# CEC1736_S0_2ZW register map
Vendor: Microchip Technology; Series: CEC; File version: 0
CPU: CM4 r1p0, little endian, MPU, FPU, 3 interrupt priority bits, 196 interrupts
Registers are 32-bit, read-write, reset 0x0 unless marked. A register's access mark holds for its fields unless they carry their own. Offsets are from the block's base; [hi:lo] are bit positions; {n}, {i} and the like mark numbered series; 'fields as' and 'values as' point back to an identical list.

## GPIO — GPIO Pin Control Registers
Base 0x40081000; register names take the prefix GPIO_
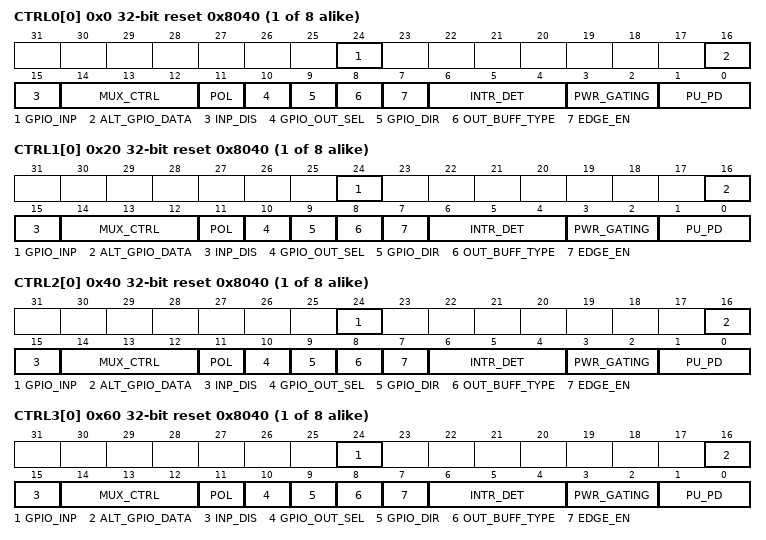
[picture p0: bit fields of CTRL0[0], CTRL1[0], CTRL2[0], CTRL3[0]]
{0x0+4i} CTRL0[{i}] (i=0..7) reset 0x8040 — GPIO Pin Control Register
  [24] GPIO_INP — GPIO input from pin, independent of the Mux selection for the pin or the Direction.
  [16] ALT_GPIO_DATA — GPIO Alternate Data Register.
  [15] INP_DIS — GPIO input disable
  [14:12] MUX_CTRL — 00 = GPIO Function, 01 = Function 1, 10 = Function 2, 11 = Function 3.
    0=GPIO (GPIO function selected); 1=FUNC1 (Signal function 1 selected); 2=FUNC2 (Signal function 2 selected); 3=FUNC3 (Signal function 3 selected)
  [11] POL — 1=Inverted; 0=Non-inverted
  [10] GPIO_OUT_SEL — GPIO outputs registe select.0=GPIO ALTERNATE_GPIO_DATA 1=GPIO Output Register.
  [9] GPIO_DIR — Buffer direction when GPIO selected by pin mux 0 = Input, 1 = Output
  [8] OUT_BUFF_TYPE — 0 = Push-Pull, 1 = Open Drain
  [7] EDGE_EN — Determines the interrupt capability of the GPIO input.
  [6:4] INTR_DET — Determines the interrupt capability of the GPIO input.
  [3:2] PWR_GATING — The GPIO pin will be tristated when the selected power well is off.
  [1:0] PU_PD — These bits are used to enable an internal pull-up or pull-down resistor.
    0=NONE (None. Pin tristates when no active driver is present on the pin.); 1=UP (Pull Up Enabled); 2=DOWN (Pull Down Enabled); 3=REPEATER (Repeater mode. Pin is kept at previous voltage level when no active driver is present on the pin.)
{0x20+4i} CTRL1[{i}] (i=0..7) reset 0x8040 — GPIO Pin Control Register
  fields as CTRL0[0]
{0x40+4i} CTRL2[{i}] (i=0..7) reset 0x8040 — GPIO Pin Control Register
  fields as CTRL0[0]
{0x60+4i} CTRL3[{i}] (i=0..7) reset 0x8040 — GPIO Pin Control Register
  fields as CTRL0[0]
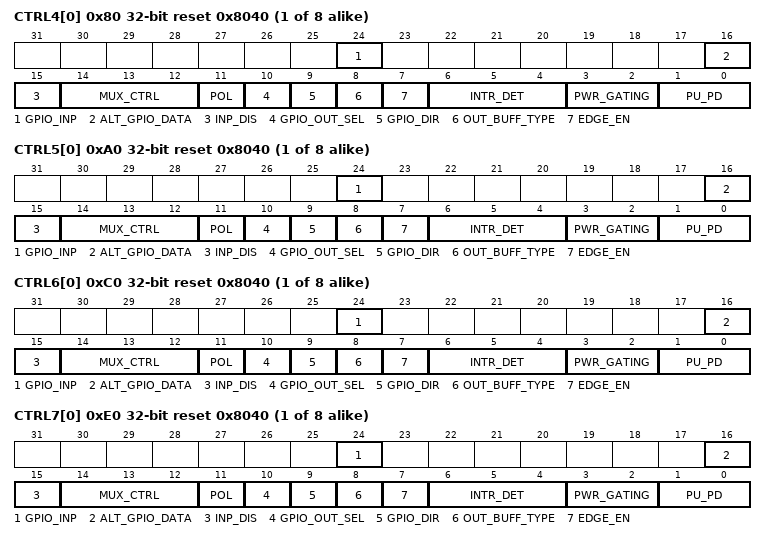
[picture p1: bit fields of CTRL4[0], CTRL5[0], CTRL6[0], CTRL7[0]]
{0x80+4i} CTRL4[{i}] (i=0..7) reset 0x8040 — GPIO Pin Control Register
  fields as CTRL0[0]
{0xA0+4i} CTRL5[{i}] (i=0..7) reset 0x8040 — GPIO Pin Control Register
  fields as CTRL0[0]
{0xC0+4i} CTRL6[{i}] (i=0..7) reset 0x8040 — GPIO Pin Control Register
  fields as CTRL0[0]
{0xE0+4i} CTRL7[{i}] (i=0..7) reset 0x8040 — GPIO Pin Control Register
  fields as CTRL0[0]
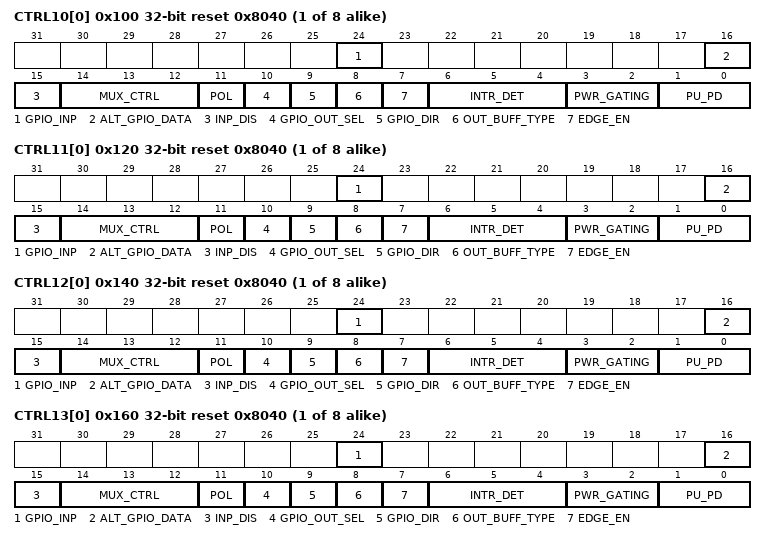
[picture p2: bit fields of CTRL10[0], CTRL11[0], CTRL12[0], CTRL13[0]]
{0x100+4i} CTRL10[{i}] (i=0..7) reset 0x8040 — GPIO Pin Control Register
  fields as CTRL0[0]
{0x120+4i} CTRL11[{i}] (i=0..7) reset 0x8040 — GPIO Pin Control Register
  fields as CTRL0[0]
{0x140+4i} CTRL12[{i}] (i=0..7) reset 0x8040 — GPIO Pin Control Register
  fields as CTRL0[0]
{0x160+4i} CTRL13[{i}] (i=0..7) reset 0x8040 — GPIO Pin Control Register
  fields as CTRL0[0]
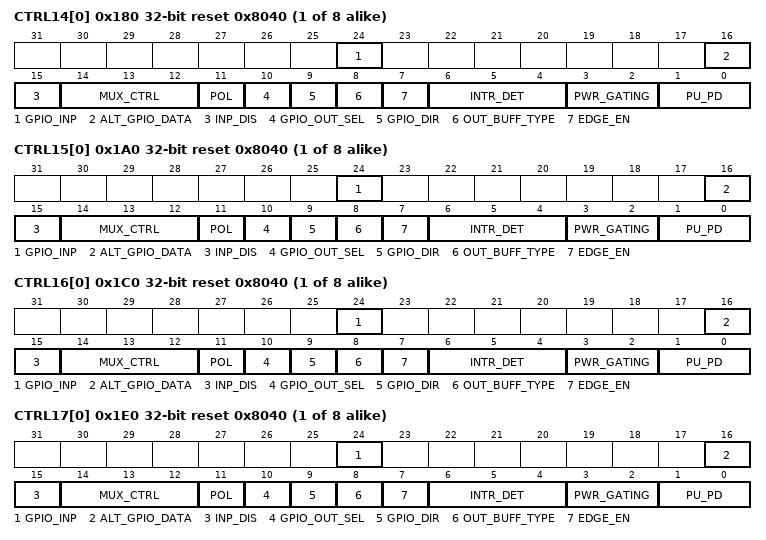
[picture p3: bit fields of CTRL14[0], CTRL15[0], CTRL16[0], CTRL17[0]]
{0x180+4i} CTRL14[{i}] (i=0..7) reset 0x8040 — GPIO Pin Control Register
  fields as CTRL0[0]
{0x1A0+4i} CTRL15[{i}] (i=0..7) reset 0x8040 — GPIO Pin Control Register
  fields as CTRL0[0]
{0x1C0+4i} CTRL16[{i}] (i=0..7) reset 0x8040 — GPIO Pin Control Register
  fields as CTRL0[0]
{0x1E0+4i} CTRL17[{i}] (i=0..7) reset 0x8040 — GPIO Pin Control Register
  fields as CTRL0[0]
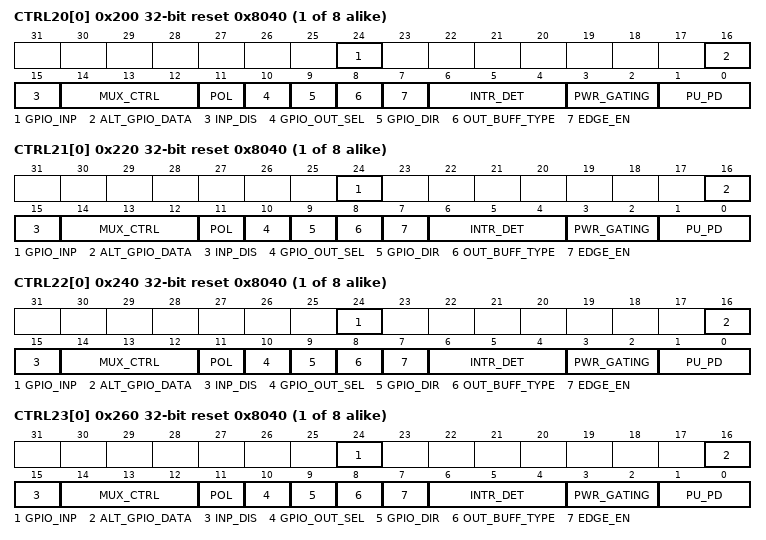
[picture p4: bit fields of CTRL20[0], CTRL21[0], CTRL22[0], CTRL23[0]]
{0x200+4i} CTRL20[{i}] (i=0..7) reset 0x8040 — GPIO Pin Control Register
  fields as CTRL0[0]
{0x220+4i} CTRL21[{i}] (i=0..7) reset 0x8040 — GPIO Pin Control Register
  fields as CTRL0[0]
{0x240+4i} CTRL22[{i}] (i=0..7) reset 0x8040 — GPIO Pin Control Register
  fields as CTRL0[0]
{0x260+4i} CTRL23[{i}] (i=0..7) reset 0x8040 — GPIO Pin Control Register
  fields as CTRL0[0]
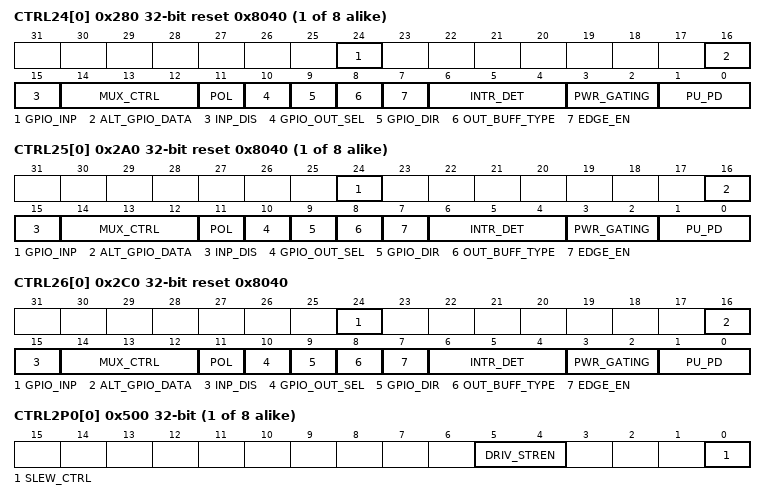
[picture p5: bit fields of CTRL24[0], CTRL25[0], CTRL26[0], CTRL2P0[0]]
{0x280+4i} CTRL24[{i}] (i=0..7) reset 0x8040 — GPIO Pin Control Register
  fields as CTRL0[0]
{0x2A0+4i} CTRL25[{i}] (i=0..7) reset 0x8040 — GPIO Pin Control Register
  fields as CTRL0[0]
{0x2C0+4i} CTRL26[{i}] (i=0..0) reset 0x8040 — GPIO Pin Control Register
  fields as CTRL0[0]
{0x300+4i} PARIN[{i}] (i=0..5) — The GPIO Input Registers.
{0x380+4i} PAROUT[{i}] (i=0..5) — The GPIO Output Registers.
{0x500+4i} CTRL2P0[{i}] (i=0..7) — The GPIO PIN_CTRL2 Registers
  [5:4] DRIV_STREN — Selects the drive strength on the pin. 00 = 2mA, 01 = 4mA, 10 = 8mA, 11 = 12mA
    0=LEVEL0 (For PIO12 = 2mA, PIO24 = 4mA); 1=LEVEL1 (For PIO12 = 4mA, PIO24 = 8mA); 2=LEVEL2 (For PIO12 = 8mA, PIO24 = 16mA); 3=LEVEL3 (For PIO12 = 12mA, PIO24 = 24mA)
  [0] SLEW_CTRL — Selects slew rate on the pin. 1=fast 0=slow
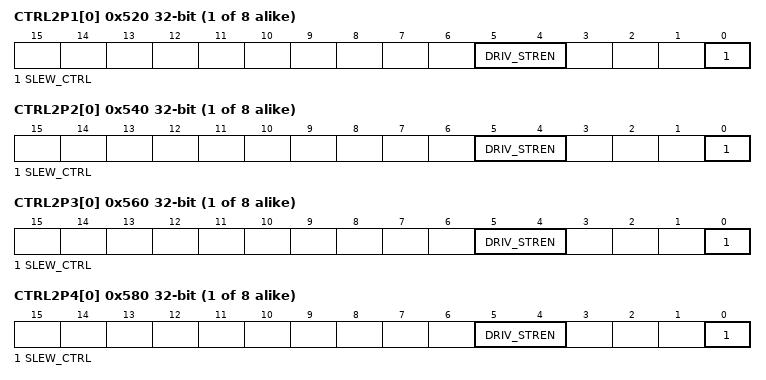
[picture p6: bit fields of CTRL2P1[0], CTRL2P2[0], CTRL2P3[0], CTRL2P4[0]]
{0x520+4i} CTRL2P1[{i}] (i=0..7) — The GPIO PIN_CTRL2 Registers
  fields as CTRL2P0[0]
{0x540+4i} CTRL2P2[{i}] (i=0..7) — The GPIO PIN_CTRL2 Registers
  fields as CTRL2P0[0]
{0x560+4i} CTRL2P3[{i}] (i=0..7) — The GPIO PIN_CTRL2 Registers
  fields as CTRL2P0[0]
{0x580+4i} CTRL2P4[{i}] (i=0..7) — The GPIO PIN_CTRL2 Registers
  fields as CTRL2P0[0]
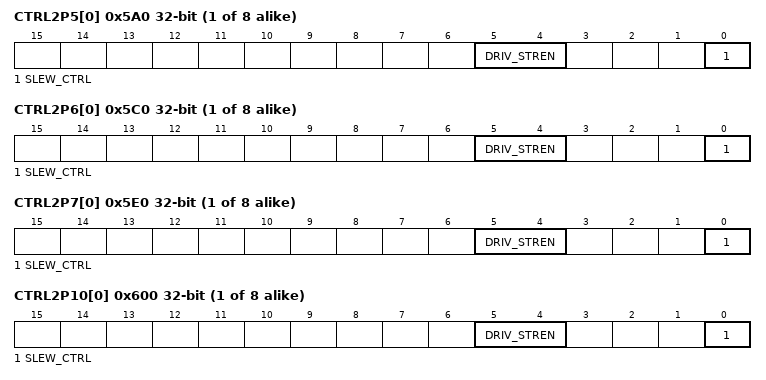
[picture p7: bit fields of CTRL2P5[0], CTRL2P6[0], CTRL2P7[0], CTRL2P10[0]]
{0x5A0+4i} CTRL2P5[{i}] (i=0..7) — The GPIO PIN_CTRL2 Registers
  fields as CTRL2P0[0]
{0x5C0+4i} CTRL2P6[{i}] (i=0..7) — The GPIO PIN_CTRL2 Registers
  fields as CTRL2P0[0]
{0x5E0+4i} CTRL2P7[{i}] (i=0..7) — The GPIO PIN_CTRL2 Registers
  fields as CTRL2P0[0]
{0x600+4i} CTRL2P10[{i}] (i=0..7) — The GPIO PIN_CTRL2 Registers
  fields as CTRL2P0[0]
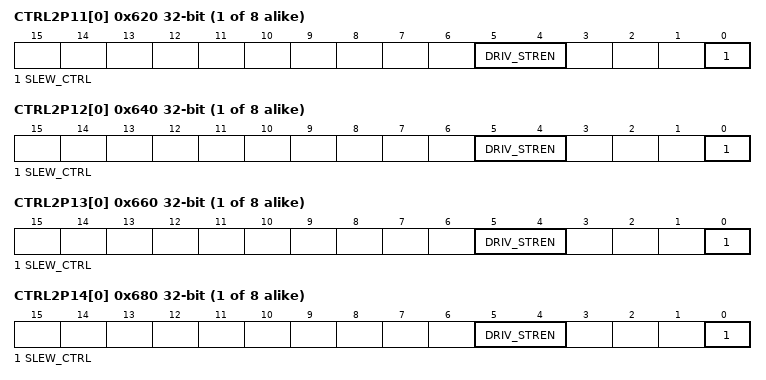
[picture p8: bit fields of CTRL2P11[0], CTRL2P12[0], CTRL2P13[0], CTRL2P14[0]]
{0x620+4i} CTRL2P11[{i}] (i=0..7) — The GPIO PIN_CTRL2 Registers
  fields as CTRL2P0[0]
{0x640+4i} CTRL2P12[{i}] (i=0..7) — The GPIO PIN_CTRL2 Registers
  fields as CTRL2P0[0]
{0x660+4i} CTRL2P13[{i}] (i=0..7) — The GPIO PIN_CTRL2 Registers
  fields as CTRL2P0[0]
{0x680+4i} CTRL2P14[{i}] (i=0..7) — The GPIO PIN_CTRL2 Registers
  fields as CTRL2P0[0]
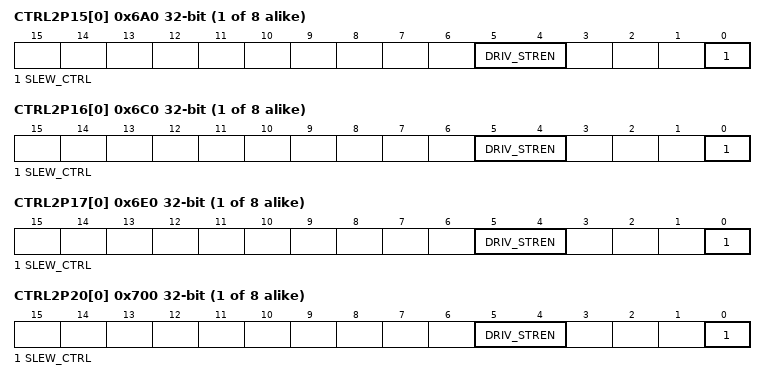
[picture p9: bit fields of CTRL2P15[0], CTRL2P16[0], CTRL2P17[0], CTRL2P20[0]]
{0x6A0+4i} CTRL2P15[{i}] (i=0..7) — The GPIO PIN_CTRL2 Registers
  fields as CTRL2P0[0]
{0x6C0+4i} CTRL2P16[{i}] (i=0..7) — The GPIO PIN_CTRL2 Registers
  fields as CTRL2P0[0]
{0x6E0+4i} CTRL2P17[{i}] (i=0..7) — The GPIO PIN_CTRL2 Registers
  fields as CTRL2P0[0]
{0x700+4i} CTRL2P20[{i}] (i=0..7) — The GPIO PIN_CTRL2 Registers
  fields as CTRL2P0[0]
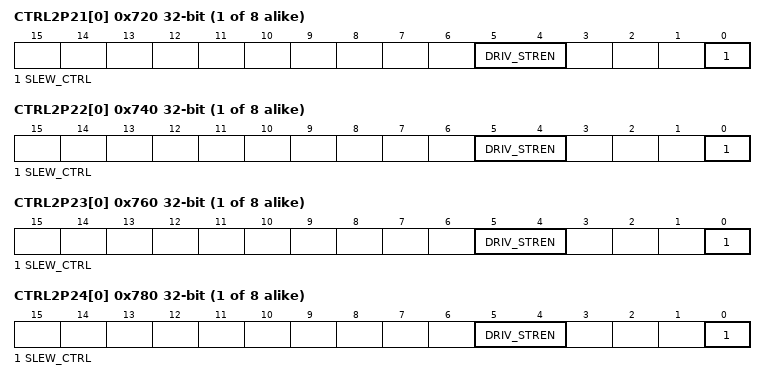
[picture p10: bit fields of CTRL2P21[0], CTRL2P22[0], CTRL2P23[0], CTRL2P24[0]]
{0x720+4i} CTRL2P21[{i}] (i=0..7) — The GPIO PIN_CTRL2 Registers
  fields as CTRL2P0[0]
{0x740+4i} CTRL2P22[{i}] (i=0..7) — The GPIO PIN_CTRL2 Registers
  fields as CTRL2P0[0]
{0x760+4i} CTRL2P23[{i}] (i=0..7) — The GPIO PIN_CTRL2 Registers
  fields as CTRL2P0[0]
{0x780+4i} CTRL2P24[{i}] (i=0..7) — The GPIO PIN_CTRL2 Registers
  fields as CTRL2P0[0]
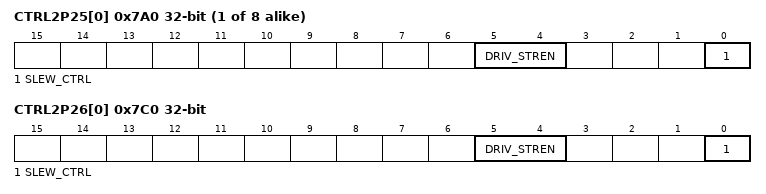
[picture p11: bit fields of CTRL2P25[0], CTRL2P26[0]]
{0x7A0+4i} CTRL2P25[{i}] (i=0..7) — The GPIO PIN_CTRL2 Registers
  fields as CTRL2P0[0]
{0x7C0+4i} CTRL2P26[{i}] (i=0..0) — The GPIO PIN_CTRL2 Registers
  fields as CTRL2P0[0]

## Notices in the file
Copyright (c) 2023 Microchip Technology Inc.
SPDX-License-Identifier: Apache-2.0
Licensed under the Apache License, Version 2.0 (the "License");
you may not use this file except in compliance with the License.
You may obtain a copy of the License at
http://www.apache.org/licenses/LICENSE-2.0
Unless required by applicable law or agreed to in writing, software
distributed under the License is distributed on an "AS IS" BASIS,
WITHOUT WARRANTIES OR CONDITIONS OF ANY KIND, either express or implied.
See the License for the specific language governing permissions and
limitations under the License.
